# R7FA2A1AB register map
Vendor: Renesas; Series: RA2; File version: 1.1
CPU: CM23 r1p0, little endian, MPU, no FPU, VTOR, 2 interrupt priority bits
Registers are 8-bit, read-write, reset 0x0 unless marked. A register's access mark holds for its fields unless they carry their own. Offsets are from the block's base; [hi:lo] are bit positions; {n}, {i} and the like mark numbered series; 'fields as' and 'values as' point back to an identical list.

## PFS — Pmn Pin Function Control Register
Base 0x40040800
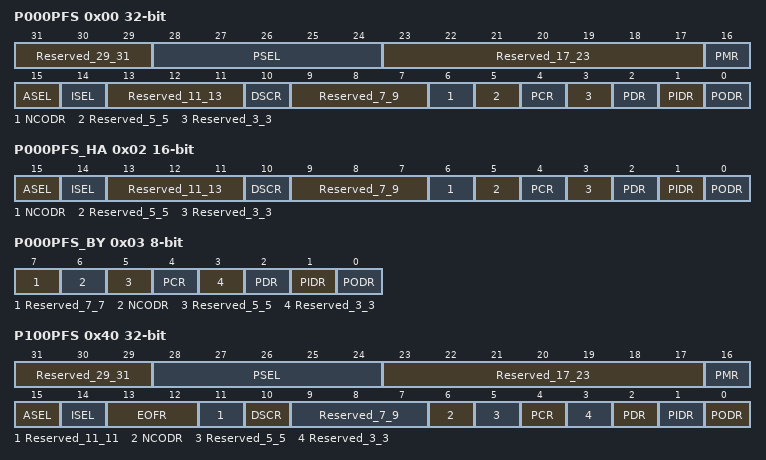
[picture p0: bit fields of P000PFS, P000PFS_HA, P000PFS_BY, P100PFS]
0x00 P000PFS 32-bit — P000 Pin Function Control Register
  [31:29] Reserved_29_31 — These bits are read as 000. The write value should be 000.
  [28:24] PSEL — Port Function Select These bits select the peripheral function. For individual pin functions, see the MPC table
  [23:17] Reserved_17_23 — These bits are read as 0000000. The write value should be 0000000.
  [16] PMR — Port Mode Control
  [15] ASEL — Analog Input enable
  [14] ISEL — IRQ input enable
  [13:11] Reserved_11_13 — These bits are read as 000. The write value should be 000.
  [10] DSCR — Drive Strength Control Register
  [9:7] Reserved_7_9 — These bits are read as 000. The write value should be 000.
  [6] NCODR — N,Channel Open Drain Control
  [5] Reserved_5_5 — This bit is read as 0. The write value should be 0.
  [4] PCR — Pull,up Control
  [3] Reserved_3_3 — This bit is read as 0. The write value should be 0.
  [2] PDR — Port Direction
  [1] PIDR ro — Port Input Data
  [0] PODR — Port Output Data
0x02 P000PFS_HA 16-bit — P000 Pin Function Control Register
  [15] ASEL — Analog Input enable
  [14] ISEL — IRQ input enable
  [13:11] Reserved_11_13 — These bits are read as 000. The write value should be 000.
  [10] DSCR — Drive Strength Control Register
  [9:7] Reserved_7_9 — These bits are read as 000. The write value should be 000.
  [6] NCODR — N,Channel Open Drain Control
  [5] Reserved_5_5 — This bit is read as 0. The write value should be 0.
  [4] PCR — Pull,up Control
  [3] Reserved_3_3 — This bit is read as 0. The write value should be 0.
  [2] PDR — Port Direction
  [1] PIDR ro — Port Input Data
  [0] PODR — Port Output Data
0x03 P000PFS_BY — P000 Pin Function Control Register
  [7] Reserved_7_7 — This bit is read as 0. The write value should be 0.
  [6] NCODR — N,Channel Open Drain Control
  [5] Reserved_5_5 — This bit is read as 0. The write value should be 0.
  [4] PCR — Pull,up Control
  [3] Reserved_3_3 — This bit is read as 0. The write value should be 0.
  [2] PDR — Port Direction
  [1] PIDR ro — Port Input Data
  [0] PODR — Port Output Data
{0x0+4i} P00{i}PFS (i=1..3) 32-bit — P00{i} Pin Function Control Register
{0x2+4i} P00{i}PFS_HA (i=1..3) 16-bit — P00{i} Pin Function Control Register
{0x3+4i} P00{i}PFS_BY (i=1..3) — P00{i} Pin Function Control Register
{0x0+4i} P0{i}PFS (i=12..15) 32-bit — P0{i} Pin Function Control Register
{0x2+4i} P0{i}PFS_HA (i=12..15) 16-bit — P0{i} Pin Function Control Register
{0x3+4i} P0{i}PFS_BY (i=12..15) — P0{i} Pin Function Control Register
0x40 P100PFS 32-bit — P100 Pin Function Control Register
  [31:29] Reserved_29_31 — These bits are read as 000. The write value should be 000.
  [28:24] PSEL — Port Function Select These bits select the peripheral function. For individual pin functions, see the MPC table
  [23:17] Reserved_17_23 — These bits are read as 0000000. The write value should be 0000000.
  [16] PMR — Port Mode Control
  [15] ASEL — Analog Input enable
  [14] ISEL — IRQ input enable
  [13:12] EOFR — Event on Falling/Event on Rising
  [11] Reserved_11_11 — This bit is read as 0. The write value should be 0.
  [10] DSCR — Drive Strength Control Register
  [9:7] Reserved_7_9 — These bits are read as 000. The write value should be 000.
  [6] NCODR — N,Channel Open Drain Control
  [5] Reserved_5_5 — This bit is read as 0. The write value should be 0.
  [4] PCR — Pull,up Control
  [3] Reserved_3_3 — This bit is read as 0. The write value should be 0.
  [2] PDR — Port Direction
  [1] PIDR ro — Port Input Data
  [0] PODR — Port Output Data
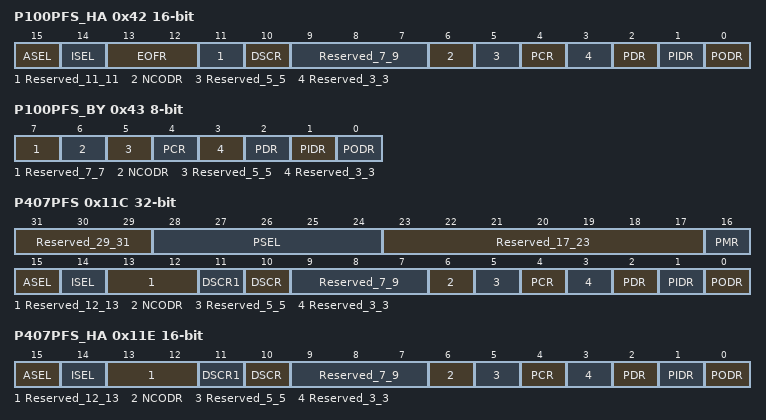
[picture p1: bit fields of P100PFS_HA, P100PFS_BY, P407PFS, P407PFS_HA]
0x42 P100PFS_HA 16-bit — P100 Pin Function Control Register
  [15] ASEL — Analog Input enable
  [14] ISEL — IRQ input enable
  [13:12] EOFR — Event on Falling/Event on Rising
  [11] Reserved_11_11 — This bit is read as 0. The write value should be 0.
  [10] DSCR — Drive Strength Control Register
  [9:7] Reserved_7_9 — These bits are read as 000. The write value should be 000.
  [6] NCODR — N,Channel Open Drain Control
  [5] Reserved_5_5 — This bit is read as 0. The write value should be 0.
  [4] PCR — Pull,up Control
  [3] Reserved_3_3 — This bit is read as 0. The write value should be 0.
  [2] PDR — Port Direction
  [1] PIDR ro — Port Input Data
  [0] PODR — Port Output Data
0x43 P100PFS_BY — P100 Pin Function Control Register
  fields as P000PFS_BY
{0x40+4i} P10{i}PFS (i=1..7) 32-bit — P10{i} Pin Function Control Register
{0x42+4i} P10{i}PFS_HA (i=1..7) 16-bit — P10{i} Pin Function Control Register
{0x43+4i} P10{i}PFS_BY (i=1..7) — P10{i} Pin Function Control Register
0x60 P108PFS 32-bit reset 0x10010 — P108 Pin Function Control Register
0x62 P108PFS_HA 16-bit reset 0x10 — P108 Pin Function Control Register
0x63 P108PFS_BY reset 0x10 — P108 Pin Function Control Register
0x64 P109PFS 32-bit — P109 Pin Function Control Register
0x66 P109PFS_HA 16-bit — P109 Pin Function Control Register
0x67 P109PFS_BY — P109 Pin Function Control Register
{0x40+4i} P1{i}PFS (i=10..12) 32-bit — P1{i} Pin Function Control Register
{0x42+4i} P1{i}PFS_HA (i=10..12) 16-bit — P1{i} Pin Function Control Register
{0x43+4i} P1{i}PFS_BY (i=10..12) — P1{i} Pin Function Control Register
0x80 P200PFS 32-bit — P200 Pin Function Control Register
0x82 P200PFS_HA 16-bit — P200 Pin Function Control Register
0x83 P200PFS_BY — P200 Pin Function Control Register
0x84 P201PFS 32-bit reset 0x10 — P201 Pin Function Control Register
0x86 P201PFS_HA 16-bit reset 0x10 — P201 Pin Function Control Register
0x87 P201PFS_BY reset 0x10 — P201 Pin Function Control Register
{0x80+4i} P20{i}PFS (i=4..6) 32-bit — P20{i} Pin Function Control Register
{0x82+4i} P20{i}PFS_HA (i=4..6) 16-bit — P20{i} Pin Function Control Register
{0x83+4i} P20{i}PFS_BY (i=4..6) — P20{i} Pin Function Control Register
{0x80+4i} P2{i}PFS (i=12..15) 32-bit — P2{i} Pin Function Control Register
{0x82+4i} P2{i}PFS_HA (i=12..15) 16-bit — P2{i} Pin Function Control Register
{0x83+4i} P2{i}PFS_BY (i=12..15) — P2{i} Pin Function Control Register
0xC0 P300PFS 32-bit reset 0x10010 — P300 Pin Function Control Register
0xC2 P300PFS_HA 16-bit reset 0x10 — P300 Pin Function Control Register
0xC3 P300PFS_BY reset 0x10 — P300 Pin Function Control Register
{0xC0+4i} P30{i}PFS (i=1..4) 32-bit — P30{i} Pin Function Control Register
{0xC2+4i} P30{i}PFS_HA (i=1..4) 16-bit — P30{i} Pin Function Control Register
{0xC3+4i} P30{i}PFS_BY (i=1..4) — P30{i} Pin Function Control Register
{0x100+4i} P40{i}PFS (i=0..3) 32-bit — P40{i} Pin Function Control Register
{0x102+4i} P40{i}PFS_HA (i=0..3) 16-bit — P40{i} Pin Function Control Register
{0x103+4i} P40{i}PFS_BY (i=0..3) — P40{i} Pin Function Control Register
0x11C P407PFS 32-bit — P407 Pin Function Control Register
  [31:29] Reserved_29_31 — These bits are read as 000. The write value should be 000.
  [28:24] PSEL — Port Function Select These bits select the peripheral function. For individual pin functions, see the MPC table
  [23:17] Reserved_17_23 — These bits are read as 0000000. The write value should be 0000000.
  [16] PMR — Port Mode Control
  [15] ASEL — Analog Input enable
  [14] ISEL — IRQ input enable
  [13:12] Reserved_12_13 — These bits are read as 00. The write value should be 00.
  [11] DSCR1 — Drive Strength Control Register
  [10] DSCR
  [9:7] Reserved_7_9 — These bits are read as 000. The write value should be 000.
  [6] NCODR — N,Channel Open Drain Control
  [5] Reserved_5_5 — This bit is read as 0. The write value should be 0.
  [4] PCR — Pull,up Control
  [3] Reserved_3_3 — This bit is read as 0. The write value should be 0.
  [2] PDR — Port Direction
  [1] PIDR ro — Port Input Data
  [0] PODR — Port Output Data
0x11E P407PFS_HA 16-bit — P407 Pin Function Control Register
  [15] ASEL — Analog Input enable
  [14] ISEL — IRQ input enable
  [13:12] Reserved_12_13 — These bits are read as 00. The write value should be 00.
  [11] DSCR1 — Drive Strength Control Register
  [10] DSCR
  [9:7] Reserved_7_9 — These bits are read as 000. The write value should be 000.
  [6] NCODR — N,Channel Open Drain Control
  [5] Reserved_5_5 — This bit is read as 0. The write value should be 0.
  [4] PCR — Pull,up Control
  [3] Reserved_3_3 — This bit is read as 0. The write value should be 0.
  [2] PDR — Port Direction
  [1] PIDR ro — Port Input Data
  [0] PODR — Port Output Data
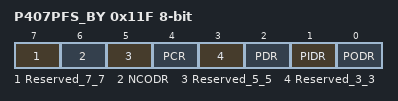
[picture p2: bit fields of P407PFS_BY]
0x11F P407PFS_BY — P407 Pin Function Control Register
  fields as P000PFS_BY
{0x100+4i} P40{i}PFS_1 (i=8..9) 32-bit — P40{i} Pin Function Control Register
{0x102+4i} P40{i}PFS_HA_1 (i=8..9) 16-bit — P40{i} Pin Function Control Register
{0x103+4i} P40{i}PFS_BY_1 (i=8..9) — P40{i} Pin Function Control Register
{0x100+4i} P4{i}PFS (i=10..11) 32-bit — P4{i} Pin Function Control Register
{0x102+4i} P4{i}PFS_HA (i=10..11) 16-bit — P4{i} Pin Function Control Register
{0x103+4i} P4{i}PFS_BY (i=10..11) — P4{i} Pin Function Control Register
{0x140+4i} P50{i}PFS (i=0..2) 32-bit — P50{i} Pin Function Control Register
{0x142+4i} P50{i}PFS_HA (i=0..2) 16-bit — P50{i} Pin Function Control Register
{0x143+4i} P50{i}PFS_BY (i=0..2) — P50{i} Pin Function Control Register
0x278 P914PFS 32-bit reset 0x10000 — P914 Pin Function Control Register
0x27A P914PFS_HA 16-bit — P914 Pin Function Control Register
0x27B P914PFS_BY — P914 Pin Function Control Register
0x27C P915PFS 32-bit reset 0x10000 — P915 Pin Function Control Register
0x27E P915PFS_HA 16-bit — P915 Pin Function Control Register
0x27F P915PFS_BY — P915 Pin Function Control Register
